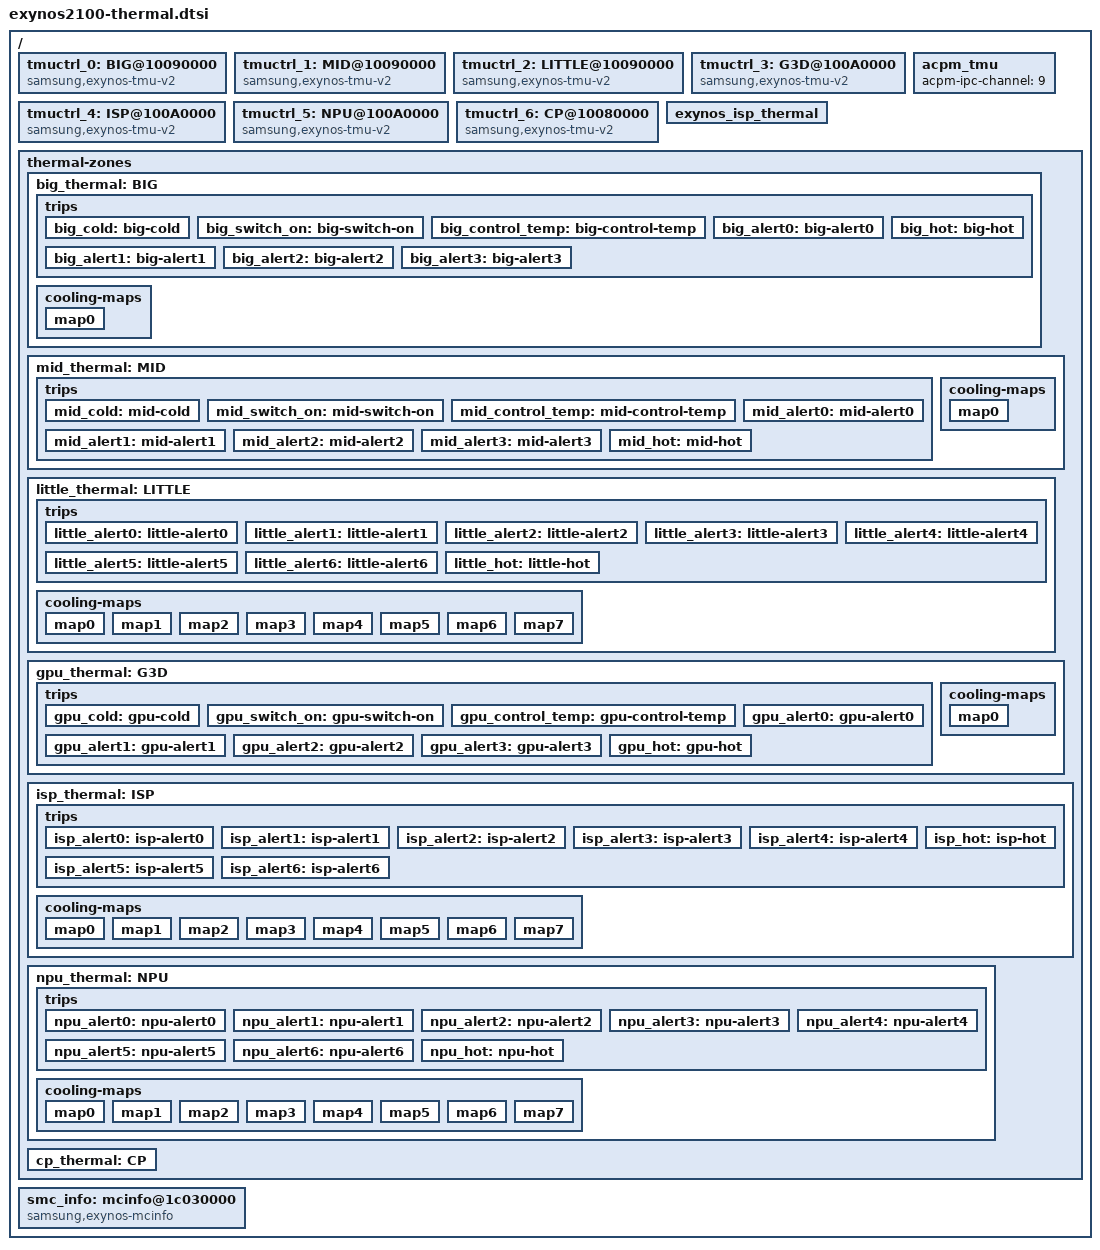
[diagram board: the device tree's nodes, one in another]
/*
 * SAMSUNG EXYNOS2100 SoC DVFS Manager device tree source
 *
 * Copyright (c) 2014 Samsung Electronics Co., Ltd.
 *		http://www.samsung.com
 *
 * SAMSUNG EXYNOS2100 SoC device nodes are listed in this file.
 * EXYNOS based board files can include this file and provide
 * values for board specfic bindings.
 *
 * This program is free software; you can redistribute it and/or modify
 * it under the terms of the GNU General Public License version 2 as
 * published by the Free Software Foundation.
 */

/ {
	tmuctrl_0: BIG@10090000 {
		compatible = "samsung,exynos-tmu-v2";
		reg = <0x0 0x10090000 0x800>;
		interrupts = <GIC_SPI INTREQ__TMU_TMU_TOP IRQ_TYPE_LEVEL_HIGH>;
		tmu_name = "BIG";
		id = <0>;
		hotplug_enable = <1>;
		hotplug_in_threshold = <91>;
		hotplug_out_threshold = <96>;
		cpu_domain = "7";
		#thermal-sensor-cells = <0>;

		use-pi-thermal;
		polling_delay_on = <50>;
		polling_delay_off = <1000>;
		k_po = <0>;
		k_pu = <0>;
		k_i = <0>;
		i_max = <0>;
		integral_cutoff = <0>;
		sustainable_power = <0>;
	};

	tmuctrl_1: MID@10090000 {
		compatible = "samsung,exynos-tmu-v2";
		reg = <0x0 0x10090000 0x800>;
		interrupts = <GIC_SPI INTREQ__TMU_TMU_TOP IRQ_TYPE_LEVEL_HIGH>;
		tmu_name = "MID";
		hotplug_enable = <1>;
		hotplug_in_threshold = <91>;
		hotplug_out_threshold = <96>;
		cpu_domain = "4-6";
		id = <1>;
		#thermal-sensor-cells = <0>;

		use-pi-thermal;
		polling_delay_on = <50>;
		polling_delay_off = <1000>;
		k_po = <0>;
		k_pu = <0>;
		k_i = <0>;
		i_max = <0>;
		integral_cutoff = <0>;
		sustainable_power = <0>;
	};

	tmuctrl_2: LITTLE@10090000 {
		compatible = "samsung,exynos-tmu-v2";
		reg = <0x0 0x10090000 0x800>;
		interrupts = <GIC_SPI INTREQ__TMU_TMU_TOP IRQ_TYPE_LEVEL_HIGH>;
		tmu_name = "LITTLE";
		id = <2>;
		#thermal-sensor-cells = <0>;
	};

	tmuctrl_3: G3D@100A0000 {
		compatible = "samsung,exynos-tmu-v2";
		reg = <0x0 0x100A0000 0x800>;
		interrupts = <GIC_SPI INTREQ__TMU_TMU_SUB IRQ_TYPE_LEVEL_HIGH>;
		tmu_name = "G3D";
		id = <3>;
		#thermal-sensor-cells = <0>;

		use-pi-thermal;
		polling_delay_on = <100>;
		polling_delay_off = <1000>;
		k_po = <0>;
		k_pu = <0>;
		k_i = <0>;
		i_max = <0>;
		integral_cutoff = <0>;
		sustainable_power = <0>;
	};

	tmuctrl_4: ISP@100A0000 {
		compatible = "samsung,exynos-tmu-v2";
		reg = <0x0 0x10090000 0x800>;
		interrupts = <GIC_SPI INTREQ__TMU_TMU_TOP IRQ_TYPE_LEVEL_HIGH>;
		tmu_name = "ISP";
		id = <4>;
		#thermal-sensor-cells = <0>;
	};

	tmuctrl_5: NPU@100A0000 {
		compatible = "samsung,exynos-tmu-v2";
		reg = <0x0 0x100A0000 0x800>;
		interrupts = <GIC_SPI INTREQ__TMU_TMU_SUB IRQ_TYPE_LEVEL_HIGH>;
		tmu_name = "NPU";
		id = <5>;
		#thermal-sensor-cells = <0>;
	};

	tmuctrl_6: CP@10080000 {
		compatible = "samsung,exynos-tmu-v2";
		reg = <0x0 0x100B0000 0x800>;
		interrupts = <GIC_SPI INTREQ__TMU_TMU_SUB IRQ_TYPE_LEVEL_HIGH>;
		tmu_name = "CP";
		id = <6>;
		#thermal-sensor-cells = <0>;
	};

	acpm_tmu {
		acpm-ipc-channel = <9>;
	};

	exynos_isp_thermal: exynos_isp_thermal {
		#cooling-cells = <2>; /* min followed by max */
	};

	thermal-zones {
		big_thermal: BIG {
			zone_name  = "BIG_THERMAL";
			polling-delay-passive = <0>;
			polling-delay = <0>;
			thermal-sensors = <&tmuctrl_0>;

			trips {
				big_cold: big-cold {
					temperature = <20000>;
					hysteresis = <5000>; /* millicelsius */
					type = "active";
				};
				big_switch_on: big-switch-on {
					temperature = <60000>; /* millicelsius */
					hysteresis = <2000>; /* millicelsius */
					type = "active";
				};
				big_control_temp: big-control-temp {
					temperature = <70000>; /* millicelsius */
					hysteresis = <5000>; /* millicelsius */
					type = "passive";
				};
				big_alert0: big-alert0 {
					temperature = <95000>; /* millicelsius */
					hysteresis = <5000>; /* millicelsius */
					type = "active";
				};
				big_alert1: big-alert1 {
					temperature = <100000>; /* millicelsius */
					hysteresis = <5000>; /* millicelsius */
					type = "active";
				};
				big_alert2: big-alert2 {
					temperature = <105000>; /* millicelsius */
					hysteresis = <5000>; /* millicelsius */
					type = "active";
				};
				big_alert3: big-alert3 {
					temperature = <110000>; /* millicelsius */
					hysteresis = <5000>; /* millicelsius */
					type = "active";
				};
				big_hot: big-hot {
					temperature = <115000>; /* millicelsius */
					hysteresis = <5000>; /* millicelsius */
					type = "hot";
				};
			};
			cooling-maps {
				map0 {
					trip = <&big_control_temp>;
					cooling-device = <&cpufreq_domain2 0 0>;
				};
			};
		};

		mid_thermal: MID {
			zone_name  = "MID_THERMAL";
			polling-delay-passive = <0>;
			polling-delay = <0>;
			thermal-sensors = <&tmuctrl_1>;

			trips {
				mid_cold: mid-cold {
					temperature = <20000>;
					hysteresis = <5000>; /* millicelsius */
					type = "active";
				};
				mid_switch_on: mid-switch-on {
					temperature = <60000>; /* millicelsius */
					hysteresis = <2000>; /* millicelsius */
					type = "active";
				};
				mid_control_temp: mid-control-temp {
					temperature = <70000>; /* millicelsius */
					hysteresis = <5000>; /* millicelsius */
					type = "passive";
				};
				mid_alert0: mid-alert0 {
					temperature = <95000>; /* millicelsius */
					hysteresis = <5000>; /* millicelsius */
					type = "active";
				};
				mid_alert1: mid-alert1 {
					temperature = <100000>; /* millicelsius */
					hysteresis = <5000>; /* millicelsius */
					type = "active";
				};
				mid_alert2: mid-alert2 {
					temperature = <105000>; /* millicelsius */
					hysteresis = <5000>; /* millicelsius */
					type = "active";
				};
				mid_alert3: mid-alert3 {
					temperature = <110000>; /* millicelsius */
					hysteresis = <5000>; /* millicelsius */
					type = "active";
				};
				mid_hot: mid-hot {
					temperature = <115000>; /* millicelsius */
					hysteresis = <5000>; /* millicelsius */
					type = "hot";
				};
			};
			cooling-maps {
				map0 {
					trip = <&mid_control_temp>;
					cooling-device = <&cpufreq_domain1 0 0>;
				};
			};
		};

		little_thermal: LITTLE {
			zone_name  = "LITTLE_THERMAL";
			polling-delay-passive = <0>;
			polling-delay = <0>;
			thermal-sensors = <&tmuctrl_2>;

			trips {
				little_alert0: little-alert0 {
					temperature = <20000>; /* millicelsius */
					hysteresis = <5000>; /* millicelsius */
					type = "active";
				};
				little_alert1: little-alert1 {
					temperature = <76000>; /* millicelsius */
					hysteresis = <5000>; /* millicelsius */
					type = "active";
				};
				little_alert2: little-alert2 {
					temperature = <81000>; /* millicelsius */
					hysteresis = <5000>; /* millicelsius */
					type = "active";
				};
				little_alert3: little-alert3 {
					temperature = <86000>; /* millicelsius */
					hysteresis = <5000>; /* millicelsius */
					type = "active";
				};
				little_alert4: little-alert4 {
					temperature = <91000>; /* millicelsius */
					hysteresis = <5000>; /* millicelsius */
					type = "active";
				};
				little_alert5: little-alert5 {
					temperature = <96000>; /* millicelsius */
					hysteresis = <5000>; /* millicelsius */
					type = "active";
				};
				little_alert6: little-alert6 {
					temperature = <101000>; /* millicelsius */
					hysteresis = <5000>; /* millicelsius */
					type = "active";
				};
				little_hot: little-hot {
					temperature = <115000>; /* millicelsius */
					hysteresis = <5000>; /* millicelsius */
					type = "hot";
				};
			};
			cooling-maps {
				map0 {
					trip = <&little_alert0>;
					cooling-device = <&cpufreq_domain0 0 0>;
				};
				map1 {
					trip = <&little_alert1>;
					cooling-device = <&cpufreq_domain0 0 0>;
				};
				map2 {
					trip = <&little_alert2>;
					cooling-device = <&cpufreq_domain0 0 0>;
				};
				map3 {
					trip = <&little_alert3>;
					cooling-device = <&cpufreq_domain0 0 0>;
				};
				map4 {
					trip = <&little_alert4>;
					cooling-device = <&cpufreq_domain0 0 0>;
				};
				map5 {
					trip = <&little_alert5>;
					cooling-device = <&cpufreq_domain0 0 0>;
				};
				map6 {
					trip = <&little_alert6>;
					cooling-device = <&cpufreq_domain0 0 0>;
				};
				map7 {
					trip = <&little_hot>;
					cooling-device = <&cpufreq_domain0 0 0>;
				};
			};
		};

		gpu_thermal: G3D {
			zone_name  = "G3D_THERMAL";
			polling-delay-passive = <0>;
			polling-delay = <0>;
			thermal-sensors = <&tmuctrl_3>;

			trips {
				gpu_cold: gpu-cold {
					temperature = <20000>;
					hysteresis = <5000>; /* millicelsius */
					type = "active";
				};
				gpu_switch_on: gpu-switch-on {
					temperature = <65000>; /* millicelsius */
					hysteresis = <2000>; /* millicelsius */
					type = "active";
				};
				gpu_control_temp: gpu-control-temp {
					temperature = <70000>; /* millicelsius */
					hysteresis = <5000>; /* millicelsius */
					type = "passive";
				};
				gpu_alert0: gpu-alert0 {
					temperature = <95000>; /* millicelsius */
					hysteresis = <5000>; /* millicelsius */
					type = "active";
				};
				gpu_alert1: gpu-alert1 {
					temperature = <100000>; /* millicelsius */
					hysteresis = <5000>; /* millicelsius */
					type = "active";
				};
				gpu_alert2: gpu-alert2 {
					temperature = <105000>; /* millicelsius */
					hysteresis = <5000>; /* millicelsius */
					type = "active";
				};
				gpu_alert3: gpu-alert3 {
					temperature = <110000>; /* millicelsius */
					hysteresis = <5000>; /* millicelsius */
					type = "active";
				};
				gpu_hot: gpu-hot {
					temperature = <115000>; /* millicelsius */
					hysteresis = <5000>; /* millicelsius */
					type = "hot";
				};
			};
			cooling-maps {
				map0 {
					trip = <&gpu_control_temp>;
					cooling-device = <&mali 0 0>;
				};
			};
		};

		isp_thermal: ISP {
			zone_name  = "ISP_THERMAL";
			polling-delay-passive = <0>;
			polling-delay = <0>;
			thermal-sensors = <&tmuctrl_4>;

			trips {
				isp_alert0: isp-alert0 {
					temperature = <20000>; /* millicelsius */
					hysteresis = <5000>; /* millicelsius */
					type = "active";
				};
				isp_alert1: isp-alert1 {
					temperature = <95000>; /* millicelsius */
					hysteresis = <5000>; /* millicelsius */
					type = "active";
				};
				isp_alert2: isp-alert2 {
					temperature = <100000>; /* millicelsius */
					hysteresis = <5000>; /* millicelsius */
					type = "active";
				};
				isp_alert3: isp-alert3 {
					temperature = <105000>; /* millicelsius */
					hysteresis = <5000>; /* millicelsius */
					type = "active";
				};
				isp_alert4: isp-alert4 {
					temperature = <110000>; /* millicelsius */
					hysteresis = <5000>; /* millicelsius */
					type = "active";
				};
				isp_alert5: isp-alert5 {
					temperature = <115000>; /* millicelsius */
					hysteresis = <5000>; /* millicelsius */
					type = "active";
				};
				isp_alert6: isp-alert6 {
					temperature = <115000>; /* millicelsius */
					hysteresis = <5000>; /* millicelsius */
					type = "active";
				};
				isp_hot: isp-hot {
					temperature = <115000>; /* millicelsius */
					hysteresis = <5000>; /* millicelsius */
					type = "hot";
				};
			};

			cooling-maps {
				map0 {
					trip = <&isp_alert0>;
					cooling-device = <&exynos_isp_thermal 0 0>;
				};
				map1 {
					trip = <&isp_alert1>;
					cooling-device = <&exynos_isp_thermal 0 0>;
				};
				map2 {
					trip = <&isp_alert2>;
					cooling-device = <&exynos_isp_thermal 0 0>;
				};
				map3 {
					trip = <&isp_alert3>;
					cooling-device = <&exynos_isp_thermal 0 0>;
				};
				map4 {
					trip = <&isp_alert4>;
					cooling-device = <&exynos_isp_thermal 0 0>;
				};
				map5 {
					trip = <&isp_alert5>;
					cooling-device = <&exynos_isp_thermal 0 0>;
				};
				map6 {
					trip = <&isp_alert6>;
					cooling-device = <&exynos_isp_thermal 0 0>;
				};
				map7 {
					trip = <&isp_hot>;
					cooling-device = <&exynos_isp_thermal 0 0>;
				};
			};
		};

		npu_thermal: NPU {
			zone_name  = "NPU_THERMAL";
			polling-delay-passive = <0>;
			polling-delay = <0>;
			thermal-sensors = <&tmuctrl_5>;

			trips {
				npu_alert0: npu-alert0 {
					temperature = <20000>; /* millicelsius */
					hysteresis = <5000>; /* millicelsius */
					type = "active";
				};
				npu_alert1: npu-alert1 {
					temperature = <76000>; /* millicelsius */
					hysteresis = <5000>; /* millicelsius */
					type = "active";
				};
				npu_alert2: npu-alert2 {
					temperature = <81000>; /* millicelsius */
					hysteresis = <5000>; /* millicelsius */
					type = "active";
				};
				npu_alert3: npu-alert3 {
					temperature = <86000>; /* millicelsius */
					hysteresis = <5000>; /* millicelsius */
					type = "active";
				};
				npu_alert4: npu-alert4 {
					temperature = <91000>; /* millicelsius */
					hysteresis = <5000>; /* millicelsius */
					type = "active";
				};
				npu_alert5: npu-alert5 {
					temperature = <96000>; /* millicelsius */
					hysteresis = <5000>; /* millicelsius */
					type = "active";
				};
				npu_alert6: npu-alert6 {
					temperature = <101000>; /* millicelsius */
					hysteresis = <5000>; /* millicelsius */
					type = "active";
				};
				npu_hot: npu-hot {
					temperature = <115000>; /* millicelsius */
					hysteresis = <5000>; /* millicelsius */
					type = "hot";
				};
			};

			cooling-maps {
				map0 {
					trip = <&npu_alert0>;
					cooling-device = <&devfreq_5 0 0>;
				};
				map1 {
					trip = <&npu_alert1>;
					cooling-device = <&devfreq_5 0 0>;
				};
				map2 {
					trip = <&npu_alert2>;
					cooling-device = <&devfreq_5 0 0>;
				};
				map3 {
					trip = <&npu_alert3>;
					cooling-device = <&devfreq_5 0 0>;
				};
				map4 {
					trip = <&npu_alert4>;
					cooling-device = <&devfreq_5 0 0>;
				};
				map5 {
					trip = <&npu_alert5>;
					cooling-device = <&devfreq_5 0 0>;
				};
				map6 {
					trip = <&npu_alert6>;
					cooling-device = <&devfreq_5 0 0>;
				};
				map7 {
					trip = <&npu_hot>;
					cooling-device = <&devfreq_5 0 0>;
				};
			};
		};
		cp_thermal: CP {
			zone_name = "CP_THERMAL";
			polling-delay-passive = <0>;
			polling-delay = <0>;
			thermal-sensors = <&tmuctrl_6>;
		};
	};

	smc_info: mcinfo@1c030000 {
			compatible = "samsung,exynos-mcinfo";
			reg = <0x0 0x1C03F04C 0x4>,
			      <0x0 0x1C13F04C 0x4>,
			      <0x0 0x1C23F04C 0x4>,
			      <0x0 0x1C33F04C 0x4>;
			bit_field = <24 5>;
			/* start bit, width */
			basecnt = <4>;
			irqcnt = <4>;

			interrupts = <GIC_SPI INTREQ__DMC_TEMPERR_MIF0 IRQ_TYPE_LEVEL_HIGH>,
				     <GIC_SPI INTREQ__DMC_TEMPERR_MIF1 IRQ_TYPE_LEVEL_HIGH>,
				     <GIC_SPI INTREQ__DMC_TEMPERR_MIF2 IRQ_TYPE_LEVEL_HIGH>,
				     <GIC_SPI INTREQ__DMC_TEMPERR_MIF3 IRQ_TYPE_LEVEL_HIGH>;
	};
};
